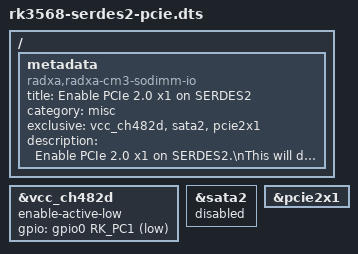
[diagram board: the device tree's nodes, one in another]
/dts-v1/;
/plugin/;

#include <dt-bindings/gpio/gpio.h>
#include <dt-bindings/pinctrl/rockchip.h>

/ {
	metadata {
		title = "Enable PCIe 2.0 x1 on SERDES2";
		compatible = "radxa,radxa-cm3-sodimm-io";
		category = "misc";
		exclusive = "vcc_ch482d", "sata2", "pcie2x1";
		description = "Enable PCIe 2.0 x1 on SERDES2.\nThis will disable SATA2.";
	};

	fragment@0 {
		target = <&vcc_ch482d>;

		__overlay__ {
			enable-active-low;
			gpio = <&gpio0 RK_PC1 GPIO_ACTIVE_LOW>;
		};
	};

	fragment@1 {
		target = <&sata2>;

		__overlay__ {
			status = "disabled";
		};
	};

	fragment@3 {
		target = <&pcie2x1>;

		__overlay__ {
			status = "okay";
		};
	};
};
